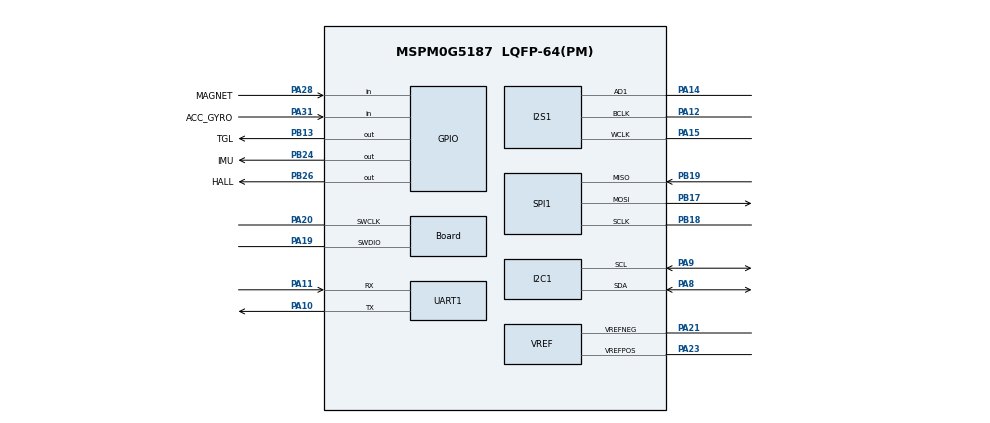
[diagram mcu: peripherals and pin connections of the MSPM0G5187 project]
//@cliArgs --device "MSPM0G518X" --package "LQFP-64(PM)" --part "Default"
//@v2CliArgs --device "MSPM0G5187" --package "LQFP-64(PM)"
// @cliArgs --board /ti/boards/LP_MSPM0G5187 --rtos nortos

/**
 * Import the modules used in this configuration.
 */
const ADC12         = scripting.addModule("/ti/driverlib/ADC12", {}, false);
const ADC121        = ADC12.addInstance();
const Board         = scripting.addModule("/ti/driverlib/Board");
const DMA           = scripting.addModule("/ti/driverlib/DMA");
const GPIO          = scripting.addModule("/ti/driverlib/GPIO", {}, false);
const GPIO1         = GPIO.addInstance();
const GPIO2         = GPIO.addInstance();
const GPIO3         = GPIO.addInstance();
const I2C           = scripting.addModule("/ti/driverlib/I2C", {}, false);
const I2C1          = I2C.addInstance();
const I2S           = scripting.addModule("/ti/driverlib/I2S", {}, false);
const I2S1          = I2S.addInstance();
const SPI           = scripting.addModule("/ti/driverlib/SPI", {}, false);
const SPI1          = SPI.addInstance();
const SYSCTL        = scripting.addModule("/ti/driverlib/SYSCTL");
const TIMER         = scripting.addModule("/ti/driverlib/TIMER", {}, false);
const TIMER1        = TIMER.addInstance();
const UART          = scripting.addModule("/ti/driverlib/UART", {}, false);
const UART1         = UART.addInstance();
const VREF          = scripting.addModule("/ti/driverlib/VREF");
const ProjectConfig = scripting.addModule("/ti/project_config/ProjectConfig");

/**
 * Write custom configuration values to the imported modules.
 */
const divider7       = system.clockTree["PLL_PDIV"];
divider7.divideValue = 2;

const divider9       = system.clockTree["UDIV"];
divider9.divideValue = 2;

const multiplier2         = system.clockTree["PLL_QDIV"];
multiplier2.multiplyValue = 5;

const mux7       = system.clockTree["HSCLKMUX"];
mux7.inputSelect = "HSCLKMUX_SYSPLL2X";

ADC121.$name               = "ADC12_0";
ADC121.enabledInterrupts   = ["DL_ADC12_INTERRUPT_MEM0_RESULT_LOADED"];
ADC121.sampCnt             = 1;
ADC121.enabledDMATriggers  = ["DL_ADC12_DMA_MEM0_RESULT_LOADED"];
ADC121.adcMem0vrefm        = "VREFM";
ADC121.sampClkDiv          = "DL_ADC12_CLOCK_DIVIDE_16";
ADC121.sampleTime0         = "40 us";
ADC121.trigSrc             = "DL_ADC12_TRIG_SRC_EVENT";
ADC121.subChanID           = 1;
ADC121.repeatMode          = true;
ADC121.adcMem0trig         = "DL_ADC12_TRIGGER_MODE_TRIGGER_NEXT";
ADC121.adcMem0chansel      = "DL_ADC12_INPUT_CHAN_2";
ADC121.resolution          = "DL_ADC12_SAMP_CONV_RES_8_BIT";
ADC121.peripheral.$assign  = "ADC0";
ADC121.adcPin2Config.$name = "ti_driverlib_gpio_GPIOPinGeneric0";

Board.peripheral.$assign          = "DEBUGSS";
Board.peripheral.swclkPin.$assign = "PA20";
Board.peripheral.swdioPin.$assign = "PA19";

GPIO1.$name                         = "DEBUG";
GPIO1.associatedPins[0].$name       = "TGL";
GPIO1.associatedPins[0].pin.$assign = "PB13";

GPIO2.$name                         = "SENSOR_INTR";
GPIO2.associatedPins.create(2);
GPIO2.associatedPins[0].direction   = "INPUT";
GPIO2.associatedPins[0].polarity    = "FALL";
GPIO2.associatedPins[0].interruptEn = true;
GPIO2.associatedPins[0].$name       = "ACC_GYRO";
GPIO2.associatedPins[0].pin.$assign = "PA31";
GPIO2.associatedPins[1].$name       = "MAGNET";
GPIO2.associatedPins[1].direction   = "INPUT";
GPIO2.associatedPins[1].interruptEn = true;
GPIO2.associatedPins[1].polarity    = "FALL";
GPIO2.associatedPins[1].pin.$assign = "PA28";

GPIO3.$name                          = "CS";
GPIO3.associatedPins.create(2);
GPIO3.associatedPins[0].$name        = "IMU";
GPIO3.associatedPins[0].initialValue = "SET";
GPIO3.associatedPins[0].pin.$assign  = "PB24";
GPIO3.associatedPins[1].initialValue = "SET";
GPIO3.associatedPins[1].$name        = "HALL";
GPIO3.associatedPins[1].pin.$assign  = "PB26";

I2C1.basicEnableController             = true;
I2C1.$name                             = "I2C";
I2C1.peripheral.$assign                = "UC1";
I2C1.peripheral.sdaPin.$assign         = "PA8";
I2C1.peripheral.sclPin.$assign         = "PA9";
I2C1.sdaPinConfig.enableConfig         = true;
I2C1.sdaPinConfig.internalResistor     = "PULL_UP";
I2C1.sclPinConfig.enableConfig         = true;
I2C1.sclPinConfig.internalResistor     = "PULL_UP";

I2S1.$name                      = "I2S_0";
I2S1.phase                      = "DUAL";
I2S1.sampleWordLength           = 32;
I2S1.dataDelay                  = "ONE";
I2S1.memoryAccessLength         = "32";
I2S1.dataPin1Enable             = true;
I2S1.dataPin1ValidChannelMask   = 3;
I2S1.wordBaudClockSource        = "INTERNAL";
I2S1.wclkPhase                  = "DUAL";
I2S1.wclkDivider                = 32;
I2S1.bclkDivider                = 8;
I2S1.peripheral.$assign         = "I2S0";
I2S1.peripheral.AD1Pin.$assign  = "PA14";
I2S1.peripheral.BCLKPin.$assign = "PA12";
I2S1.peripheral.WCLKPin.$assign = "PA15";

SPI1.$name                              = "SPI";
SPI1.targetBitRate                      = 1000000;
SPI1.chipSelect                         = ["1","3"];
SPI1.frameFormat                        = "MOTO3";
SPI1.peripheral.$assign                 = "UC2";
SPI1.peripheral.sclkPin.$assign         = "PB18";
SPI1.peripheral.mosiPin.$assign         = "PB17";
SPI1.peripheral.misoPin.$assign         = "PB19";

SYSCTL.MFPCLKEn              = true;
SYSCTL.HFCLKMonitor          = true;
SYSCTL.SYSPLLSource          = "HFCLK";
SYSCTL.SYSPLL_Pdiv           = 1;
SYSCTL.SYSPLL_Qdiv           = 4;
SYSCTL.HFCLKSource           = "HFXT";
SYSCTL.HFCLK_Freq            = 40000000;
SYSCTL.useHFCLK_Manual       = true;
SYSCTL.SYSPLL_CLK2XEn        = true;
SYSCTL.SYSPLL_CLK2XDiv       = 3;
SYSCTL.forceDefaultClkConfig = true;
SYSCTL.clockTreeEn           = true;

TIMER1.timerMode                   = "PERIODIC";
TIMER1.timerClkDiv                 = 8;
TIMER1.timerClkPrescale            = 8;
TIMER1.event1PublisherChannel      = 1;
TIMER1.event1ControllerInterruptEn = ["ZERO_EVENT"];
TIMER1.$name                       = "SAMPLING_TIMER";
TIMER1.timerPeriod                 = "31.25 ms";
TIMER1.peripheral.$assign          = "TIMA0";

UART1.targetBaudRate                      = 115200;
UART1.enabledDMATXTriggers                = "DL_UART_DMA_INTERRUPT_TX";
UART1.enabledDMARXTriggers                = "DL_UART_DMA_INTERRUPT_RX";
UART1.$name                               = "UART_DAP";
UART1.peripheral.$assign                  = "UC0";
UART1.peripheral.rxPin.$assign            = "PA11";
UART1.peripheral.txPin.$assign            = "PA10";
UART1.DMA_CHANNEL_TX.$name                = "DMA_CH1";
UART1.DMA_CHANNEL_TX.addressMode          = "b2f";
UART1.DMA_CHANNEL_TX.srcLength            = "BYTE";
UART1.DMA_CHANNEL_TX.dstLength            = "BYTE";
UART1.DMA_CHANNEL_TX.enableInterrupt      = true;
UART1.DMA_CHANNEL_TX.peripheral.$assign   = "DMA_CH1";
UART1.DMA_CHANNEL_RX.$name                = "DMA_CH0";
UART1.DMA_CHANNEL_RX.addressMode          = "f2b";
UART1.DMA_CHANNEL_RX.srcLength            = "BYTE";
UART1.DMA_CHANNEL_RX.dstLength            = "BYTE";
UART1.DMA_CHANNEL_RX.enableEarlyInterrupt = true;
UART1.DMA_CHANNEL_RX.earlyIntThresh       = "64";
UART1.DMA_CHANNEL_RX.peripheral.$assign   = "DMA_CH0";

VREF.basicMode                     = "DL_VREF_ENABLE_ENABLE_DL_VREF_ENABLE_DISABLE";
VREF.basicVrefPins                 = "VREF+-";
VREF.basicExtVolt                  = 3.3;
VREF.peripheral.$assign            = "VREF";
VREF.peripheral.vrefPosPin.$assign = "PA23";
VREF.peripheral.vrefNegPin.$assign = "PA21";

ProjectConfig.migrationCondition = true;
